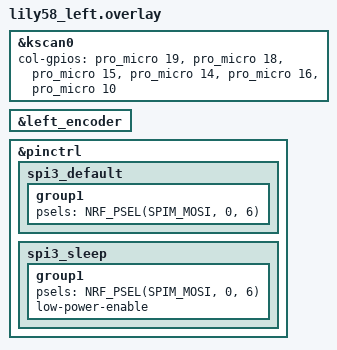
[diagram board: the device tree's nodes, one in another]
#include "lily58.dtsi"
#include <dt-bindings/led/led.h>

&kscan0 {
	col-gpios
	= <&pro_micro 19 GPIO_ACTIVE_HIGH>
	, <&pro_micro 18 GPIO_ACTIVE_HIGH>
	, <&pro_micro 15 GPIO_ACTIVE_HIGH>
	, <&pro_micro 14 GPIO_ACTIVE_HIGH>
	, <&pro_micro 16 GPIO_ACTIVE_HIGH>
	, <&pro_micro 10 GPIO_ACTIVE_HIGH>
	;
};

&left_encoder {
	status = "okay";
};

&pinctrl {
	spi3_default: spi3_default {
		group1 {
			psels = <NRF_PSEL(SPIM_MOSI, 0, 6)>;
		};
	};

	spi3_sleep: spi3_sleep {
		group1 {
			psels = <NRF_PSEL(SPIM_MOSI, 0, 6)>;
			low-power-enable;
		};
	};
};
